# CY8C4xxx register map
File version: 0.1
Registers are 8-bit, read-write, no defined reset value unless marked. A register's access mark holds for its fields unless they carry their own. Offsets are from the block's base; [hi:lo] are bit positions; {n}, {i} and the like mark numbered series; 'fields as' and 'values as' point back to an identical list.

## UDB_W32 — UDB Working Registers 32-bit mode (4 consecutive UDB's)
Base 0x400F2000; alternate view of UDB
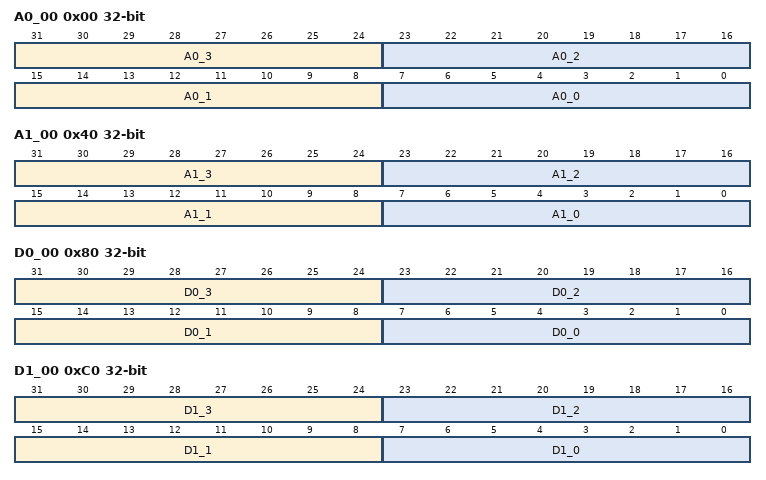
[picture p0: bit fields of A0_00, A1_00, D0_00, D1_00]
0x00 A0_00 32-bit — Accumulator 0
  [31:24] A0_3 — Accumulator 0 for UDB[n+3]
  [23:16] A0_2 — Accumulator 0 for UDB[n+2]
  [15:8] A0_1 — Accumulator 0 for UDB[n+1]
  [7:0] A0_0 — Accumulator 0 for UDB[n]
0x40 A1_00 32-bit — Accumulator 1
  [31:24] A1_3 — Accumulator 1 for UDB[n+3]
  [23:16] A1_2 — Accumulator 1 for UDB[n+2]
  [15:8] A1_1 — Accumulator 1 for UDB[n+1]
  [7:0] A1_0 — Accumulator 1 for UDB[n]
0x80 D0_00 32-bit — Data 0
  [31:24] D0_3 — Data 0 for UDB[n+3]
  [23:16] D0_2 — Data 0 for UDB[n+2]
  [15:8] D0_1 — Data 0 for UDB[n+1]
  [7:0] D0_0 — Data 0 for UDB[n]
0xC0 D1_00 32-bit — Data 1
  [31:24] D1_3 — Data 1 for UDB[n+3]
  [23:16] D1_2 — Data 1 for UDB[n+2]
  [15:8] D1_1 — Data 1 for UDB[n+1]
  [7:0] D1_0 — Data 1 for UDB[n]
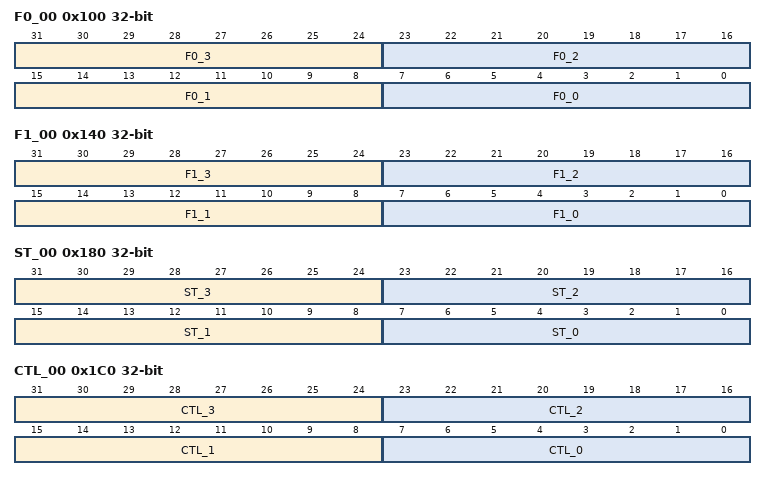
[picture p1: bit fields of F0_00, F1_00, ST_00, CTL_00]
0x100 F0_00 32-bit — FIFO 0
  [31:24] F0_3 — Fifo 0 for UDB[n+3]
  [23:16] F0_2 — Fifo 0 for UDB[n+2]
  [15:8] F0_1 — Fifo 0 for UDB[n+1]
  [7:0] F0_0 — Fifo 0 for UDB[n]
0x140 F1_00 32-bit — FIFO 1
  [31:24] F1_3 — Fifo 1 for UDB[n+3]
  [23:16] F1_2 — Fifo 1 for UDB[n+2]
  [15:8] F1_1 — Fifo 1 for UDB[n+1]
  [7:0] F1_0 — Fifo 1 for UDB[n]
0x180 ST_00 32-bit — Status Register
  [31:24] ST_3 ro — Status register for UDB[n+3]
  [23:16] ST_2 ro — Status register for UDB[n+2]
  [15:8] ST_1 ro — Status register for UDB[n+1]
  [7:0] ST_0 ro — Status register for UDB[n]
0x1C0 CTL_00 32-bit — Control Register
  [31:24] CTL_3 — Control register for UDB[n+3]
  [23:16] CTL_2 — Control register for UDB[n+2]
  [15:8] CTL_1 — Control register for UDB[n+1]
  [7:0] CTL_0 — Control register for UDB[n]
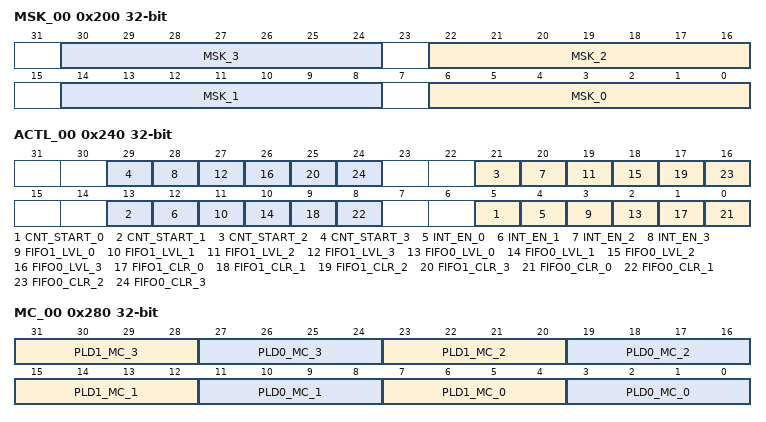
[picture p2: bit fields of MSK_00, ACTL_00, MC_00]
0x200 MSK_00 32-bit — Interrupt Mask
  [8n+6:8n] MSK_{n} (n=0..3) — Interrupt Mask Register
0x240 ACTL_00 32-bit — Auxiliary Control
  [8n+5] CNT_START_{n} (n=0..3) — Control Register Counter Enable
    0=DISABLE; 1=ENABLE
  [8n+4] INT_EN_{n} (n=0..3) — enable interrupt
    0=DISABLE; 1=ENABLE
  [8n+3] FIFO1_LVL_{n} (n=0..3) — FIFO fill status level control
    0=NORMAL; 1=MID
  [8n+2] FIFO0_LVL_{n} (n=0..3) — FIFO fill status level control
    0=NORMAL; 1=MID
  [8n+1] FIFO1_CLR_{n} (n=0..3) — FIFO clear
    0=NORMAL; 1=CLEAR
  [8n] FIFO0_CLR_{n} (n=0..3) — FIFO clear
    0=NORMAL; 1=CLEAR
0x280 MC_00 32-bit — PLD Macrocell reading
  [31:28] PLD1_MC_3 ro — Read Macrocell 1 for UDB[n+3]
  [27:24] PLD0_MC_3 ro — Read Macrocell 0 for UDB[n+3]
  [23:20] PLD1_MC_2 ro — Read Macrocell 1 for UDB[n+2]
  [19:16] PLD0_MC_2 ro — Read Macrocell 0 for UDB[n+2]
  [15:12] PLD1_MC_1 ro — Read Macrocell 1 for UDB[n+1]
  [11:8] PLD0_MC_1 ro — Read Macrocell 0 for UDB[n+1]
  [7:4] PLD1_MC_0 ro — Read Macrocell 1 for UDB[n]
  [3:0] PLD0_MC_0 ro — Read Macrocell 0 for UDB[n]

## UDB_P0_ROUTE — Routing Configuration for one UDB Pair
Base 0x400F3100; alternate view of UDB
{0x0+i} HC{i} (i=0..127) — UDB Channel HC Tile Configuration; Horizontal Channel
  [7:0] HC_BYTE — RAM configuration bytes for channel
{0x80+i} HV_L{i} (i=0..15) — UDB Channel HV Tile Configuration; Left
  [7:0] HV_BYTE — RAM configuration bytes for channel
{0x90+i} HS{i} (i=0..23) — UDB Channel HS Tile Configuration; Horizontal Segmentation
  [7:0] HS_BYTE — RAM configuration bytes for channel
{0xA8+i} HV_R{i} (i=0..15) — UDB Channel HV Tile Configuration; Right
  [7:0] HV_BYTE — RAM configuration bytes for channel
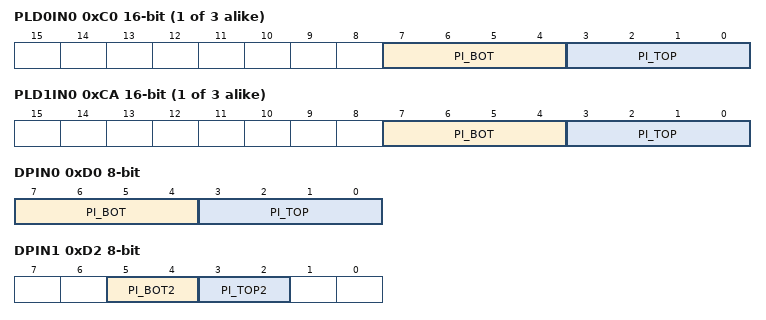
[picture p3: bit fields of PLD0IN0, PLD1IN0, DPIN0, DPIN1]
{0xC0+2i} PLD0IN{i} 16-bit (i=0..2) — UDB Channel PI Tile Configuration; PLD Input
  [7:4] PI_BOT — RAM configuration nibble for BOTTOM UDB port interface configuration
  [3:0] PI_TOP — RAM configuration nibble for TOP UDB port interface configuration
{0xCA+2i} PLD1IN{i} 16-bit (i=0..2) — UDB Channel PI Tile Configuration; PLD Input
  fields as PLD0IN0
0xD0 DPIN0 — UDB Channel PI Tile Configuration; Datapath Input
  fields as PLD0IN0
0xD2 DPIN1 — UDB Channel PI Tile Configuration; Datapath Input
  [5:4] PI_BOT2 — RAM configuration bits (2) for BOTTOM UDB port interface configuration
  [3:2] PI_TOP2 — RAM configuration bits (2) for TOP UDB port interface configuration
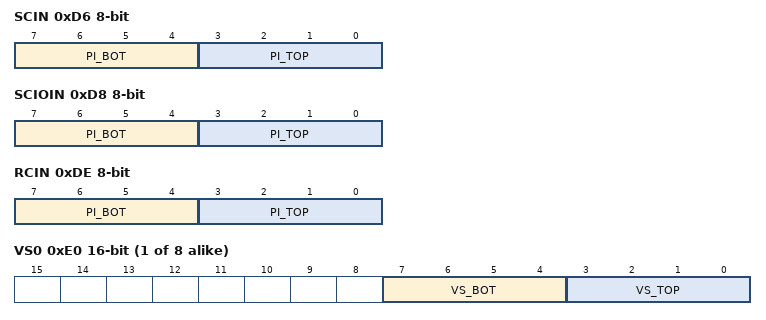
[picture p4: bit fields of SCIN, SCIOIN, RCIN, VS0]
0xD6 SCIN — UDB Channel PI Tile Configuration; Status / Control Blocks Input Control
  fields as PLD0IN0
0xD8 SCIOIN — UDB Channel PI Tile Configuration; Status / Control Blocks Input / Output Control
  fields as PLD0IN0
0xDE RCIN — UDB Channel PI Tile Configuration; Reset and Clock Blocks Input Control
  fields as PLD0IN0
{0xE0+2i} VS{i} 16-bit (i=0..7) — UDB Channel VS Tile Configuration; Vertical Segmentation
  [7:4] VS_BOT — RAM configuration nibble for BOTTOM UDB vertical segmentation configuration
  [3:0] VS_TOP — RAM configuration nibble for TOP UDB vertical segmentation configuration

## UDB_P1_ROUTE — Routing Configuration for one UDB Pair
Base 0x400F3300; alternate view of UDB
Registers as UDB_P0_ROUTE.

## UDB_DSI0 — DSI Configuration (16 DSI)
Base 0x400F4000; alternate view of UDB
{0x0+i} HC{i} (i=0..127) — DSI HC Tile Configuration
  [7:0] HC_BYTE — RAM configuration for DSI channel bytes
{0x80+i} HV_L{i} (i=0..15) — DSI HV Tile Configuration; Left
  [7:0] HV_BYTE — RAM configuration for DSI channel bytes
{0x90+i} HS{i} (i=0..23) — DSI HS Tile Configuration; Horizontal Segmentation
  [7:0] HS_BYTE — RAM configuration for DSI channel bytes
{0xA8+i} HV_R{i} (i=0..15) — DSI HV Tile Configuration; Right
  [7:0] HV_BYTE — RAM configuration for DSI channel bytes
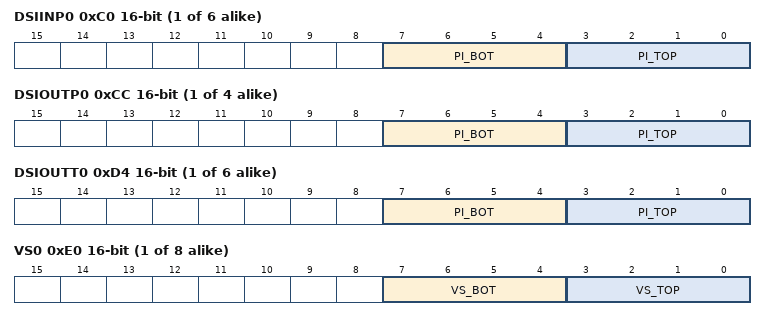
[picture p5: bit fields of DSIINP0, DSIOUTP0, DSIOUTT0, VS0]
{0xC0+2i} DSIINP{i} 16-bit (i=0..5) — DSI PI Tile Configuration for DSI I/O; Input
  [7:4] PI_BOT — RAM configuration for BOTTOM DSI port interface, not implemented in TOP DSI blocks
  [3:0] PI_TOP — RAM configuration for TOP DSI port interface, not implemented in BOTTOM DSI blocks
{0xCC+2i} DSIOUTP{i} 16-bit (i=0..3) — DSI PI Tile Configuration for DSI I/O; Output pair
  fields as DSIINP0
{0xD4+2i} DSIOUTT{i} 16-bit (i=0..5) — DSI PI Tile Configuration for DSI I/O; Output triplet
  fields as DSIINP0
{0xE0+2i} VS{i} 16-bit (i=0..7) — DSI VS Tile Configuration; Vertical Segmentation
  [7:4] VS_BOT — RAM configuration for BOTTOM DSI vertical segmentation, not implemented in TOP DSI blocks
  [3:0] VS_TOP — RAM configuration for TOP DSI vertical segmentation, not implemented in BOTTOM DSI blocks

## UDB_DSI1 — DSI Configuration (16 DSI)
Base 0x400F4100; alternate view of UDB
Registers as UDB_DSI0.

## UDB_DSI2 — DSI Configuration (16 DSI)
Base 0x400F4200; alternate view of UDB
Registers as UDB_DSI0.

## UDB_DSI3 — DSI Configuration (16 DSI)
Base 0x400F4300; alternate view of UDB
Registers as UDB_DSI0.

## UDB_UDBIF — UDB Subsystem Interface Configuration
Base 0x400F7000; alternate view of UDB
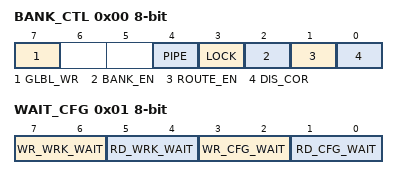
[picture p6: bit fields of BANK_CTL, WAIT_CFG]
0x00 BANK_CTL — Bank Control
  [7] GLBL_WR — UDB Array Global Writing Option
    0=DISABLE; 1=ENABLE
  [4] PIPE — Pipelining Control
    0=BYPASS; 1=PIPELINED
  [3] LOCK — UDB Array Configuration Locking
    0=MUTABLE; 1=LOCKED
  [2] BANK_EN — Enable Bank
    0=DISABLE; 1=ENABLE
  [1] ROUTE_EN — Enable Routing
    0=DISABLE; 1=ENABLE
  [0] DIS_COR — Selection of Clear-On-Read
    0=NORMAL; 1=DISABLE
0x01 WAIT_CFG — Wait States Configuration
  [7:6] WR_WRK_WAIT — Write Work Wait States
    0=ONE_WAIT; 1=TWO_WAITS; 2=THREE_WAITS; 3=ZERO_WAITS
  [5:4] RD_WRK_WAIT — Read Work Wait States
    0=ONE_WAIT; 1=TWO_WAITS; 2=THREE_WAITS; 3=ZERO_WAITS
  [3:2] WR_CFG_WAIT — Write Configuration Wait States
    0=ONE_WAIT; 1=TWO_WAITS; 2=THREE_WAITS; 3=ZERO_WAITS
  [1:0] RD_CFG_WAIT — Read Configuration Wait States
    0=FIVE_WAITS; 1=FOUR_WAITS; 2=THREE_WAITS; 3=ONE_WAIT
0x1C INT_CLK_CTL — Interrupt Synchronizer Clock Control
  [0] EN_HFCLK ro — This bit enables the interrupt synchronizer in the UDB interface. It needs to be set whenever UDB/DSI interrupts are used. Disabling the interrupt synchronizer saves power in Active/Sleep mode.
